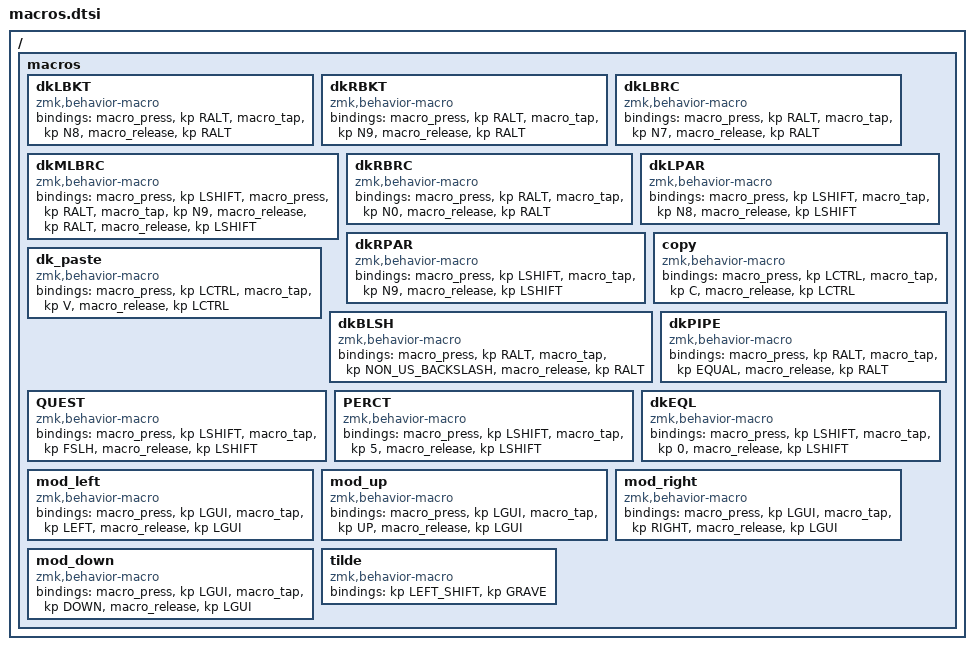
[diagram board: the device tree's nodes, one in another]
/ {
    macros {
        // Danish macros
        dkLBKT: dkLBKT {
            compatible = "zmk,behavior-macro";
            #binding-cells = <0>;
            bindings =
                <&macro_press>,
                <&kp RALT>,
                <&macro_tap>,
                <&kp N8>,
                <&macro_release>,
                <&kp RALT>;
        };

        dkRBKT: dkRBKT {
            compatible = "zmk,behavior-macro";
            #binding-cells = <0>;
            bindings =
                <&macro_press>,
                <&kp RALT>,
                <&macro_tap>,
                <&kp N9>,
                <&macro_release>,
                <&kp RALT>;
        };

        dkLBRC: dkLBRC {
            compatible = "zmk,behavior-macro";
            #binding-cells = <0>;
            bindings =
                <&macro_press>,
                <&kp RALT>,
                <&macro_tap>,
                <&kp N7>,
                <&macro_release>,
                <&kp RALT>;
        };

        dkMLBRC: dkMLBRC {
            compatible = "zmk,behavior-macro";
            #binding-cells = <0>;
            bindings =
                <&macro_press>,
                <&kp LSHIFT>,
                <&macro_press>,
                <&kp RALT>,
                <&macro_tap>,
                <&kp N8>,
                <&macro_release>,
                <&kp RALT>,
                <&macro_release>,
                <&kp LSHIFT>;
        };

        dkMLBRC: dkMLBRC {
            compatible = "zmk,behavior-macro";
            #binding-cells = <0>;
            bindings =
                <&macro_press>,
                <&kp LSHIFT>,
                <&macro_press>,
                <&kp RALT>,
                <&macro_tap>,
                <&kp N9>,
                <&macro_release>,
                <&kp RALT>,
                <&macro_release>,
                <&kp LSHIFT>;
        };

        dkRBRC: dkRBRC {
            compatible = "zmk,behavior-macro";
            #binding-cells = <0>;
            bindings =
                <&macro_press>,
                <&kp RALT>,
                <&macro_tap>,
                <&kp N0>,
                <&macro_release>,
                <&kp RALT>;
        };

        dkLPAR: dkLPAR {
            compatible = "zmk,behavior-macro";
            #binding-cells = <0>;
            bindings =
                <&macro_press>,
                <&kp LSHIFT>,
                <&macro_tap>,
                <&kp N8>,
                <&macro_release>,
                <&kp LSHIFT>;
        };

        dkRPAR: dkRPAR {
            compatible = "zmk,behavior-macro";
            #binding-cells = <0>;
            bindings =
                <&macro_press>,
                <&kp LSHIFT>,
                <&macro_tap>,
                <&kp N9>,
                <&macro_release>,
                <&kp LSHIFT>;
        };

        copy: copy {
            compatible = "zmk,behavior-macro";
            #binding-cells = <0>;
            bindings =
                <&macro_press>,
                <&kp LCTRL>,
                <&macro_tap>,
                <&kp C>,
                <&macro_release>,
                <&kp LCTRL>;
        };

        dk_paste: dk_paste {
            compatible = "zmk,behavior-macro";
            #binding-cells = <0>;
            bindings =
                <&macro_press>,
                <&kp LCTRL>,
                <&macro_tap>,
                <&kp V>,
                <&macro_release>,
                <&kp LCTRL>;
        };

        dkBLSH: dkBLSH {
            compatible = "zmk,behavior-macro";
            #binding-cells = <0>;
            bindings =
                <&macro_press>,
                <&kp RALT>,
                <&macro_tap>,
                <&kp NON_US_BACKSLASH>,
                <&macro_release>,
                <&kp RALT>;
        };

        dkPIPE: dkPIPE {
            compatible = "zmk,behavior-macro";
            #binding-cells = <0>;
            bindings =
                <&macro_press>,
                <&kp RALT>,
                <&macro_tap>,
                <&kp EQUAL>,
                <&macro_release>,
                <&kp RALT>;
        };

        QUEST: QUEST {
            compatible = "zmk,behavior-macro";
            #binding-cells = <0>;
            bindings =
                <&macro_press>,
                <&kp LSHIFT>,
                <&macro_tap>,
                <&kp FSLH>,
                <&macro_release>,
                <&kp LSHIFT>;
        };

        PERCT: PERCT {
            compatible = "zmk,behavior-macro";
            #binding-cells = <0>;
            bindings =
                <&macro_press>,
                <&kp LSHIFT>,
                <&macro_tap>,
                <&kp 5>,
                <&macro_release>,
                <&kp LSHIFT>;
        };

        dkEQL: dkEQL {
            compatible = "zmk,behavior-macro";
            #binding-cells = <0>;
            bindings =
                <&macro_press>,
                <&kp LSHIFT>,
                <&macro_tap>,
                <&kp 0>,
                <&macro_release>,
                <&kp LSHIFT>;
        };

        mod_left: mod_left {
            compatible = "zmk,behavior-macro";
            #binding-cells = <0>;
            bindings =
                <&macro_press>,
                <&kp LGUI>,
                <&macro_tap>,
                <&kp LEFT>,
                <&macro_release>,
                <&kp LGUI>;
        };

        mod_up: mod_up {
            compatible = "zmk,behavior-macro";
            #binding-cells = <0>;
            bindings =
                <&macro_press>,
                <&kp LGUI>,
                <&macro_tap>,
                <&kp UP>,
                <&macro_release>,
                <&kp LGUI>;
        };

        mod_right: mod_right {
            compatible = "zmk,behavior-macro";
            #binding-cells = <0>;
            bindings =
                <&macro_press>,
                <&kp LGUI>,
                <&macro_tap>,
                <&kp RIGHT>,
                <&macro_release>,
                <&kp LGUI>;
        };

        mod_down: mod_down {
            compatible = "zmk,behavior-macro";
            #binding-cells = <0>;
            bindings =
                <&macro_press>,
                <&kp LGUI>,
                <&macro_tap>,
                <&kp DOWN>,
                <&macro_release>,
                <&kp LGUI>;
        };
        tilde: tilde {
            compatible = "zmk,behavior-macro";
            #binding-cells = <0>;
            bindings = <&kp LEFT_SHIFT &kp GRAVE>;
        };
    };
};
